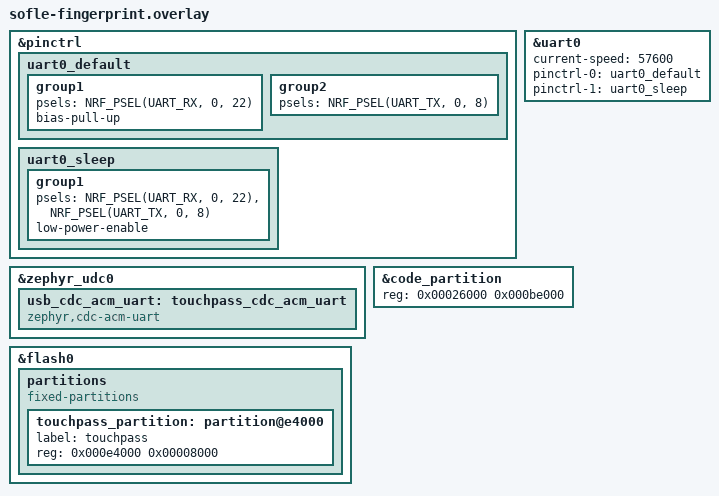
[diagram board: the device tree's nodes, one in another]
/*
 * Sofle R58 HLK-ZW0906 指纹模块覆盖配置（仅左手 / central）
 *
 * PCB 引脚定义（sofle_r58.kicad_pcb）：
 *   J6.1 GND        -> GND
 *   J6.2 RXD        -> FP_MCU_TX (U1.2 / D0 / P0.08)
 *   J6.3 TXD        -> FP_MCU_RX (U1.7 / D4 / P0.22)
 *   J6.4 VDD_3V3    -> VCC (3.3V)
 *   J6.5 Detect     -> FP_DETECT (未连接 MCU)
 *   J6.6 SENSOR_3V3 -> VCC (3.3V)
 *
 * 注意：nice!nano 默认 uart0 使用 P0.06(TX) / P0.08(RX)，其中 P0.06(D1)
 *       在本板被用作 nice!view CS，因此必须将 uart0 重映射到 P0.08(TX) / P0.22(RX)。
 */

&pinctrl {
    uart0_default: uart0_default {
        group1 {
            psels = <NRF_PSEL(UART_RX, 0, 22)>;
            bias-pull-up;
        };
        group2 {
            psels = <NRF_PSEL(UART_TX, 0, 8)>;
        };
    };

    uart0_sleep: uart0_sleep {
        group1 {
            psels = <NRF_PSEL(UART_RX, 0, 22)>,
                    <NRF_PSEL(UART_TX, 0, 8)>;
            low-power-enable;
        };
    };
};

&uart0 {
    status = "okay";
    current-speed = <57600>;
    pinctrl-0 = <&uart0_default>;
    pinctrl-1 = <&uart0_sleep>;
    pinctrl-names = "default", "sleep";
};

/* Web Serial 配置工具用 CDC ACM 串口（与 DYA Studio 的 snippet_studio_rpc_usb_uart 并存） */
&zephyr_udc0 {
    status = "okay";
    usb_cdc_acm_uart: touchpass_cdc_acm_uart {
        compatible = "zephyr,cdc-acm-uart";
    };
};

/* 从原 code_partition (0x26000..0xec000) 末尾划分 32KB 给 touchpass NVS 存储 */
&code_partition {
    reg = <0x00026000 0x000be000>;
};

&flash0 {
    partitions {
        compatible = "fixed-partitions";
        #address-cells = <1>;
        #size-cells = <1>;

        touchpass_partition: partition@e4000 {
            label = "touchpass";
            reg = <0x000e4000 0x00008000>;
        };
    };
};
